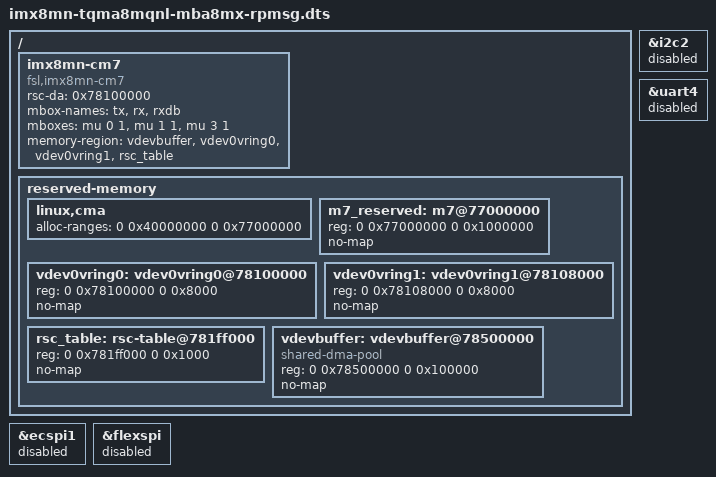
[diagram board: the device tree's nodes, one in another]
// SPDX-License-Identifier: (GPL-2.0-or-later OR MIT)
/*
 * Copyright (c) 2021-2023 TQ-Systems GmbH <linux@ew.tq-group.com>,
 * D-82229 Seefeld, Germany.
 * Author: Alexander Stein
 */

#include "imx8mn-tqma8mqnl-mba8mx.dts"

/ {

	imx8mn-cm7 {
		compatible = "fsl,imx8mn-cm7";
		rsc-da = <0x78100000>;
		mbox-names = "tx", "rx", "rxdb";
		mboxes = <&mu 0 1
			  &mu 1 1
			  &mu 3 1>;
		memory-region = <&vdevbuffer>, <&vdev0vring0>,
				<&vdev0vring1>, <&rsc_table>;
	};

	reserved-memory {
		#address-cells = <2>;
		#size-cells = <2>;
		ranges;

		/* global autoconfigured region for contiguous allocations */
		linux,cma {
			/*
			 * 640 MiB total, SOM should have at least 1024 MiB
			 * limit range to 1024 - 128 - 16 MiB, to leave room:
			 * 128 MiB generic
			 * 16 MiB: allow optional carve-out for M7 at 0x77000000
			 */
			alloc-ranges = <0 0x40000000 0 0x77000000>;
		};

		/*
		 * 0x7700_0000 ~ 0x77FF_FFFF is reserved for M7
		 * Must not be used from code running on Cortex-A cluster
		 * Must be in sync with linker settings for M7
		 */
		m7_reserved: m7@77000000 {
			reg = <0 0x77000000 0 0x1000000>;
			no-map;
		};

		vdev0vring0: vdev0vring0@78100000 {
			reg = <0 0x78100000 0 0x8000>;
			no-map;
		};

		vdev0vring1: vdev0vring1@78108000 {
			reg = <0 0x78108000 0 0x8000>;
			no-map;
		};

		rsc_table: rsc-table@781ff000 {
			reg = <0 0x781ff000 0 0x1000>;
			no-map;
		};

		vdevbuffer: vdevbuffer@78500000 {
			compatible = "shared-dma-pool";
			reg = <0 0x78500000 0 0x100000>;
			no-map;
		};
	};
};

/*
 * ATTENTION: M7 may use IPs like below
 * UART4, I2C2, ECSPI2, FLEXSPI
 * if access to more hardware is needed, keep in mind to disable it to prevent
 * system lockup and other things. Also resource partitioning using RDC
 * should beimplemented. See TF-A implementation.
 */

&ecspi1 {
	status = "disabled";
};

&flexspi {
	status = "disabled";
};

&i2c2 {
	status = "disabled";
};

&uart4 {
	status = "disabled";
};
